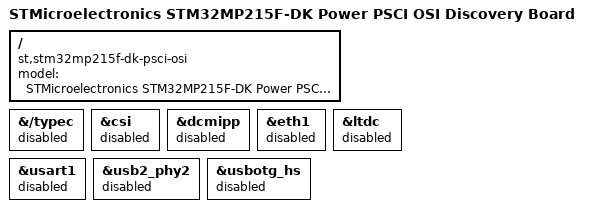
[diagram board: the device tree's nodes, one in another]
// SPDX-License-Identifier: (GPL-2.0-only OR BSD-3-Clause)
/*
 * Copyright (C) STMicroelectronics 2024 - All Rights Reserved
 */

/dts-v1/;

#include <stm32mp215f-dk.dts>

/ {
	model = "STMicroelectronics STM32MP215F-DK Power PSCI OSI Discovery Board";
	compatible = "st,stm32mp215f-dk-psci-osi", "st,stm32mp215f-dk", "st,stm32mp215";
};

/* Deactivate drivers without a full PM runtime support or with external modules */

&{/typec} {
	status = "disabled";
};

&csi {
	status = "disabled";
};

&dcmipp {
	status = "disabled";
};

&eth1 {
	status = "disabled";
};

&ltdc {
	status = "disabled";
};

&usart1 {
	status = "disabled";
};

&usb2_phy2 {
	status = "disabled";
};

&usbotg_hs {
	status = "disabled";
};
